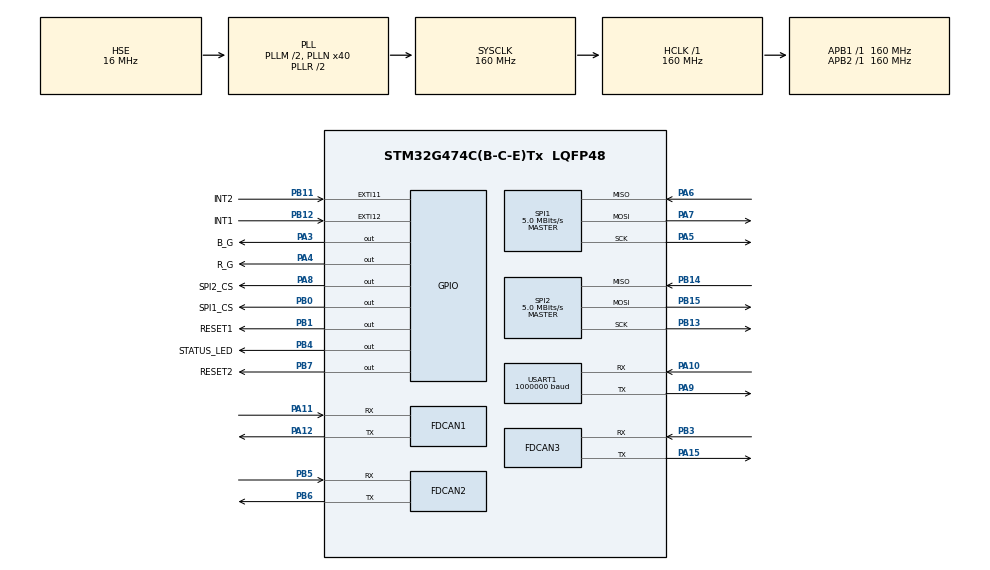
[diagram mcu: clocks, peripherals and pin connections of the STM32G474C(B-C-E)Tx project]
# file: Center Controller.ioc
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Dma.Request0=USART1_RX
Dma.Request1=USART1_TX
Dma.USART1_RX.0.Direction=DMA_PERIPH_TO_MEMORY
Dma.USART1_RX.0.EventEnable=DISABLE
Dma.USART1_RX.0.Instance=DMA1_Channel1
Dma.USART1_RX.0.MemDataAlignment=DMA_MDATAALIGN_BYTE
Dma.USART1_RX.0.MemInc=DMA_MINC_ENABLE
Dma.USART1_RX.0.Mode=DMA_CIRCULAR
Dma.USART1_RX.0.PeriphDataAlignment=DMA_PDATAALIGN_BYTE
Dma.USART1_RX.0.PeriphInc=DMA_PINC_DISABLE
Dma.USART1_RX.0.Polarity=HAL_DMAMUX_REQ_GEN_RISING
Dma.USART1_RX.0.Priority=DMA_PRIORITY_HIGH
Dma.USART1_RX.0.RequestNumber=1
Dma.USART1_RX.0.SignalID=NONE
Dma.USART1_RX.0.SyncEnable=DISABLE
Dma.USART1_RX.0.SyncPolarity=HAL_DMAMUX_SYNC_NO_EVENT
Dma.USART1_RX.0.SyncRequestNumber=1
Dma.USART1_RX.0.SyncSignalID=NONE
Dma.USART1_TX.1.Direction=DMA_MEMORY_TO_PERIPH
Dma.USART1_TX.1.EventEnable=DISABLE
Dma.USART1_TX.1.Instance=DMA1_Channel2
Dma.USART1_TX.1.MemDataAlignment=DMA_MDATAALIGN_BYTE
Dma.USART1_TX.1.MemInc=DMA_MINC_ENABLE
Dma.USART1_TX.1.Mode=DMA_NORMAL
Dma.USART1_TX.1.PeriphDataAlignment=DMA_PDATAALIGN_BYTE
Dma.USART1_TX.1.PeriphInc=DMA_PINC_DISABLE
Dma.USART1_TX.1.Polarity=HAL_DMAMUX_REQ_GEN_RISING
Dma.USART1_TX.1.Priority=DMA_PRIORITY_MEDIUM
Dma.USART1_TX.1.RequestNumber=1
Dma.USART1_TX.1.SignalID=NONE
Dma.USART1_TX.1.SyncEnable=DISABLE
Dma.USART1_TX.1.SyncPolarity=HAL_DMAMUX_SYNC_NO_EVENT
Dma.USART1_TX.1.SyncRequestNumber=1
Dma.USART1_TX.1.SyncSignalID=NONE
FDCAN1.AutoRetransmission=ENABLE
FDCAN1.CalculateBaudRateData=1000000
FDCAN1.CalculateBaudRateNominal=1000000
FDCAN1.CalculateTimeBitData=1000
FDCAN1.CalculateTimeBitNominal=1000
FDCAN1.CalculateTimeQuantumData=50.0
FDCAN1.CalculateTimeQuantumNominal=50.0
FDCAN1.ClockDivider=FDCAN_CLOCK_DIV1
FDCAN1.DataPrescaler=2
FDCAN1.DataSyncJumpWidth=4
FDCAN1.DataTimeSeg1=15
FDCAN1.DataTimeSeg2=4
FDCAN1.ExtFiltersNbr=0
FDCAN1.FrameFormat=FDCAN_FRAME_CLASSIC
FDCAN1.Mode=FDCAN_MODE_NORMAL
FDCAN1.NominalPrescaler=2
FDCAN1.NominalSyncJumpWidth=4
FDCAN1.NominalTimeSeg1=15
FDCAN1.NominalTimeSeg2=4
FDCAN1.ProtocolException=DISABLE
FDCAN1.StdFiltersNbr=4
FDCAN1.TransmitPause=DISABLE
FDCAN1.TxFifoQueueMode=FDCAN_TX_QUEUE_OPERATION
FDCAN2.AutoRetransmission=ENABLE
FDCAN2.CalculateBaudRateData=1000000
FDCAN2.CalculateBaudRateNominal=1000000
FDCAN2.CalculateTimeBitData=1000
FDCAN2.CalculateTimeBitNominal=1000
FDCAN2.CalculateTimeQuantumData=50.0
FDCAN2.CalculateTimeQuantumNominal=50.0
FDCAN2.ClockDivider=FDCAN_CLOCK_DIV1
FDCAN2.DataPrescaler=2
FDCAN2.DataSyncJumpWidth=4
FDCAN2.DataTimeSeg1=15
FDCAN2.DataTimeSeg2=4
FDCAN2.ExtFiltersNbr=0
FDCAN2.FrameFormat=FDCAN_FRAME_CLASSIC
FDCAN2.Mode=FDCAN_MODE_NORMAL
FDCAN2.NominalPrescaler=2
FDCAN2.NominalSyncJumpWidth=4
FDCAN2.NominalTimeSeg1=15
FDCAN2.NominalTimeSeg2=4
FDCAN2.ProtocolException=DISABLE
FDCAN2.StdFiltersNbr=2
FDCAN2.TransmitPause=DISABLE
FDCAN2.TxFifoQueueMode=FDCAN_TX_QUEUE_OPERATION
FDCAN3.AutoRetransmission=ENABLE
FDCAN3.CalculateBaudRateData=1000000
FDCAN3.CalculateBaudRateNominal=1000000
FDCAN3.CalculateTimeBitData=1000
FDCAN3.CalculateTimeBitNominal=1000
FDCAN3.CalculateTimeQuantumData=50.0
FDCAN3.CalculateTimeQuantumNominal=50.0
FDCAN3.ClockDivider=FDCAN_CLOCK_DIV1
FDCAN3.DataPrescaler=2
FDCAN3.DataSyncJumpWidth=4
FDCAN3.DataTimeSeg1=15
FDCAN3.DataTimeSeg2=4
FDCAN3.ExtFiltersNbr=0
FDCAN3.FrameFormat=FDCAN_FRAME_CLASSIC
FDCAN3.Mode=FDCAN_MODE_NORMAL
FDCAN3.NominalPrescaler=2
FDCAN3.NominalSyncJumpWidth=4
FDCAN3.NominalTimeSeg1=15
FDCAN3.NominalTimeSeg2=4
FDCAN3.ProtocolException=DISABLE
FDCAN3.StdFiltersNbr=2
FDCAN3.TransmitPause=DISABLE
FDCAN3.TxFifoQueueMode=FDCAN_TX_QUEUE_OPERATION
Mcu.Family=STM32G4
Mcu.Name=STM32G474C(B-C-E)Tx
Mcu.Package=LQFP48
NVIC.DMA1_Channel1_IRQn=true\:5\:0\:true\:false\:true\:false\:true\:true
NVIC.DMA1_Channel2_IRQn=true\:5\:0\:true\:false\:true\:false\:true\:true
NVIC.EXTI15_10_IRQn=true\:3\:0\:true\:false\:true\:false\:true\:true
NVIC.FDCAN1_IT0_IRQn=true\:1\:0\:true\:false\:true\:false\:true\:true
NVIC.FDCAN2_IT0_IRQn=true\:3\:0\:true\:false\:true\:false\:true\:true
NVIC.FDCAN3_IT0_IRQn=true\:3\:0\:true\:false\:true\:false\:true\:true
NVIC.PriorityGroup=NVIC_PRIORITYGROUP_4
NVIC.TIM7_DAC_IRQn=true\:2\:0\:true\:false\:true\:false\:true\:true
NVIC.USART1_IRQn=true\:5\:0\:true\:false\:true\:false\:true\:true
PA10.Mode=Asynchronous
PA10.Signal=USART1_RX
PA11.Mode=FDCAN_Activate
PA11.Signal=FDCAN1_RX
PA12.Mode=FDCAN_Activate
PA12.Signal=FDCAN1_TX
PA13.Mode=Serial_Wire
PA13.Signal=SYS_JTMS-SWDIO
PA14.Mode=Serial_Wire
PA14.Signal=SYS_JTCK-SWCLK
PA15.Mode=FDCAN_Activate
PA15.Signal=FDCAN3_TX
PA3.GPIO_Label=B_G
PA3.GPIO_ModeDefaultOutputPP=GPIO_MODE_OUTPUT_PP
PA3.GPIO_PuPd=GPIO_NOPULL
PA3.GPIO_Speed=GPIO_SPEED_FREQ_LOW
PA3.PinState=GPIO_PIN_RESET
PA3.Signal=GPIO_Output
PA4.GPIO_Label=R_G
PA4.GPIO_ModeDefaultOutputPP=GPIO_MODE_OUTPUT_PP
PA4.GPIO_PuPd=GPIO_NOPULL
PA4.GPIO_Speed=GPIO_SPEED_FREQ_LOW
PA4.PinState=GPIO_PIN_RESET
PA4.Signal=GPIO_Output
PA5.Mode=Full_Duplex_Master
PA5.Signal=SPI1_SCK
PA6.Mode=Full_Duplex_Master
PA6.Signal=SPI1_MISO
PA7.Mode=Full_Duplex_Master
PA7.Signal=SPI1_MOSI
PA8.GPIO_Label=SPI2_CS
PA8.GPIO_ModeDefaultOutputPP=GPIO_MODE_OUTPUT_PP
PA8.GPIO_PuPd=GPIO_NOPULL
PA8.GPIO_Speed=GPIO_SPEED_FREQ_LOW
PA8.PinState=GPIO_PIN_SET
PA8.Signal=GPIO_Output
PA9.Mode=Asynchronous
PA9.Signal=USART1_TX
PB0.GPIO_Label=SPI1_CS
PB0.GPIO_ModeDefaultOutputPP=GPIO_MODE_OUTPUT_PP
PB0.GPIO_PuPd=GPIO_NOPULL
PB0.GPIO_Speed=GPIO_SPEED_FREQ_LOW
PB0.PinState=GPIO_PIN_SET
PB0.Signal=GPIO_Output
PB1.GPIO_Label=RESET1
PB1.GPIO_ModeDefaultOutputPP=GPIO_MODE_OUTPUT_PP
PB1.GPIO_PuPd=GPIO_NOPULL
PB1.GPIO_Speed=GPIO_SPEED_FREQ_LOW
PB1.PinState=GPIO_PIN_SET
PB1.Signal=GPIO_Output
PB11.GPIO_Label=INT2
PB11.GPIO_ModeDefaultEXTI=GPIO_MODE_IT_FALLING
PB11.GPIO_PuPd=GPIO_NOPULL
PB11.Signal=GPXTI11
PB12.GPIO_Label=INT1
PB12.GPIO_ModeDefaultEXTI=GPIO_MODE_IT_FALLING
PB12.GPIO_PuPd=GPIO_NOPULL
PB12.Signal=GPXTI12
PB13.Mode=Full_Duplex_Master
PB13.Signal=SPI2_SCK
PB14.Mode=Full_Duplex_Master
PB14.Signal=SPI2_MISO
PB15.Mode=Full_Duplex_Master
PB15.Signal=SPI2_MOSI
PB3.Mode=FDCAN_Activate
PB3.Signal=FDCAN3_RX
PB4.GPIO_Label=STATUS_LED
PB4.GPIO_ModeDefaultOutputPP=GPIO_MODE_OUTPUT_PP
PB4.GPIO_PuPd=GPIO_NOPULL
PB4.GPIO_Speed=GPIO_SPEED_FREQ_LOW
PB4.PinState=GPIO_PIN_RESET
PB4.Signal=GPIO_Output
PB5.Mode=FDCAN_Activate
PB5.Signal=FDCAN2_RX
PB6.Mode=FDCAN_Activate
PB6.Signal=FDCAN2_TX
PB7.GPIO_Label=RESET2
PB7.GPIO_ModeDefaultOutputPP=GPIO_MODE_OUTPUT_PP
PB7.GPIO_PuPd=GPIO_NOPULL
PB7.GPIO_Speed=GPIO_SPEED_FREQ_LOW
PB7.PinState=GPIO_PIN_SET
PB7.Signal=GPIO_Output
PF0-OSC_IN.Mode=HSE-External-Oscillator
PF0-OSC_IN.Signal=RCC_OSC_IN
PF1-OSC_OUT.Mode=HSE-External-Oscillator
PF1-OSC_OUT.Signal=RCC_OSC_OUT
ProjectManager.HeapSize=0x200
ProjectManager.StackSize=0x1000
ProjectManager.TargetToolchain=CMake
RCC.ADC12Freq_Value=160000000
RCC.ADC345Freq_Value=160000000
RCC.AHBFreq_Value=160000000
RCC.APB1Freq_Value=160000000
RCC.APB1TimFreq_Value=160000000
RCC.APB2Freq_Value=160000000
RCC.APB2TimFreq_Value=160000000
RCC.CK48CLockSelection=RCC_USBCLKSOURCE_PLL
RCC.CortexFreq_Value=160000000
RCC.EXTERNAL_CLOCK_VALUE=12288000
RCC.FDCANCLockSelection=RCC_FDCANCLKSOURCE_PLL
RCC.HCLKFreq_Value=160000000
RCC.HSE_VALUE=16000000
RCC.HSI48_VALUE=48000000
RCC.HSI_VALUE=16000000
RCC.LSE_VALUE=32768
RCC.PLLM=RCC_PLLM_DIV2
RCC.PLLN=40
RCC.PLLP=RCC_PLLP_DIV2
RCC.PLLQ=RCC_PLLQ_DIV8
RCC.PLLR=RCC_PLLR_DIV2
RCC.PLLSourceVirtual=RCC_PLLSOURCE_HSE
RCC.PWR_Regulator_Voltage_Scale=PWR_REGULATOR_VOLTAGE_SCALE1_BOOST
RCC.SYSCLKFreq_VALUE=160000000
RCC.SYSCLKSource=RCC_SYSCLKSOURCE_PLLCLK
RCC.USART1CLockSelection=RCC_USART1CLKSOURCE_PCLK2
RCC.USART2CLockSelection=RCC_USART2CLKSOURCE_PCLK1
RCC.USBFreq_Value=40000000
RCC.VCOOutputFreq_Value=320000000
SPI1.BaudRatePrescaler=SPI_BAUDRATEPRESCALER_32
SPI1.CLKPhase=SPI_PHASE_1EDGE
SPI1.CLKPolarity=SPI_POLARITY_LOW
SPI1.CRCCalculation=SPI_CRCCALCULATION_DISABLE
SPI1.CalculateBaudRate=5.0 MBits/s
SPI1.DataSize=SPI_DATASIZE_8BIT
SPI1.Direction=SPI_DIRECTION_2LINES
SPI1.FirstBit=SPI_FIRSTBIT_MSB
SPI1.Mode=SPI_MODE_MASTER
SPI1.NSS=SPI_NSS_SOFT
SPI1.NSSPMode=SPI_NSS_PULSE_DISABLE
SPI1.TIMode=SPI_TIMODE_DISABLE
SPI1.VirtualType=VM_MASTER
SPI2.BaudRatePrescaler=SPI_BAUDRATEPRESCALER_32
SPI2.CLKPhase=SPI_PHASE_1EDGE
SPI2.CLKPolarity=SPI_POLARITY_LOW
SPI2.CRCCalculation=SPI_CRCCALCULATION_DISABLE
SPI2.CalculateBaudRate=5.0 MBits/s
SPI2.DataSize=SPI_DATASIZE_8BIT
SPI2.Direction=SPI_DIRECTION_2LINES
SPI2.FirstBit=SPI_FIRSTBIT_MSB
SPI2.Mode=SPI_MODE_MASTER
SPI2.NSS=SPI_NSS_SOFT
SPI2.NSSPMode=SPI_NSS_PULSE_DISABLE
SPI2.TIMode=SPI_TIMODE_DISABLE
SPI2.VirtualType=VM_MASTER
TIM7.AutoReloadPreload=TIM_AUTORELOAD_PRELOAD_DISABLE
TIM7.PeriodNoDither=999
TIM7.Prescaler=159
TIM7.TIM_MasterOutputTrigger=TIM_TRGO_RESET
USART1.BaudRate=1000000
USART1.ClockPrescaler=PRESCALER_DIV1
USART1.FIFOMode=FIFOMODE_DISABLE
USART1.Mode=MODE_TX_RX
USART1.OverSampling=UART_OVERSAMPLING_16
USART1.Parity=PARITY_NONE
USART1.StopBits=STOPBITS_1
USART1.VirtualMode-Asynchronous=VM_ASYNC
USART1.WordLength=WORDLENGTH_8B
VP_SYS_VS_DBSignals.Mode=DisableDeadBatterySignals
VP_TIM7_VS_ClockSourceINT.Mode=Enable_Timer
board=custom

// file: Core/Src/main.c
/* USER CODE BEGIN Header */
/**
  ******************************************************************************
  * @file           : main.c
  * @brief          : Main program body
  ******************************************************************************
  * @attention
  *
  * Copyright (c) 2026 STMicroelectronics.
  * All rights reserved.
  *
  * This software is licensed under terms that can be found in the LICENSE file
  * in the root directory of this software component.
  * If no LICENSE file comes with this software, it is provided AS-IS.
  *
  ******************************************************************************
  */
/* USER CODE END Header */
#include "main.h"
#include "dma.h"
#include "fdcan.h"
#include "spi.h"
#include "tim.h"
#include "usart.h"
#include "gpio.h"

/* USER CODE BEGIN Includes */
#include "board_app.h"
#include "status_led.h"

/* USER CODE END Includes */

void SystemClock_Config(void);

int main(void)
{

  /* MCU Configuration--------------------------------------------------------*/

  /* Reset of all peripherals, Initializes the Flash interface and the Systick. */
  HAL_Init();

  /* Configure the system clock */
  SystemClock_Config();

  /* Initialize all configured peripherals */
  MX_GPIO_Init();
  MX_DMA_Init();
  MX_FDCAN1_Init();
  MX_FDCAN2_Init();
  MX_FDCAN3_Init();
  MX_SPI1_Init();
  MX_SPI2_Init();
  MX_USART1_UART_Init();
  MX_TIM7_Init();
  /* USER CODE BEGIN 2 */
  BoardApp_Init();
  StatusLed_Init(HAL_GetTick());

  /* USER CODE END 2 */

  /* Infinite loop */
  while (1)
  {

    /* USER CODE BEGIN 3 */
    BoardApp_Process();
    StatusLed_Process(HAL_GetTick());
  }
  /* USER CODE END 3 */
}

void SystemClock_Config(void)
{
  RCC_OscInitTypeDef RCC_OscInitStruct = {0};
  RCC_ClkInitTypeDef RCC_ClkInitStruct = {0};

  /** Configure the main internal regulator output voltage
  */
  HAL_PWREx_ControlVoltageScaling(PWR_REGULATOR_VOLTAGE_SCALE1_BOOST);

  /** Initializes the RCC Oscillators according to the specified parameters
  * in the RCC_OscInitTypeDef structure.
  */
  RCC_OscInitStruct.OscillatorType = RCC_OSCILLATORTYPE_HSE;
  RCC_OscInitStruct.HSEState = RCC_HSE_ON;
  RCC_OscInitStruct.PLL.PLLState = RCC_PLL_ON;
  RCC_OscInitStruct.PLL.PLLSource = RCC_PLLSOURCE_HSE;
  RCC_OscInitStruct.PLL.PLLM = RCC_PLLM_DIV2;
  RCC_OscInitStruct.PLL.PLLN = 40;
  RCC_OscInitStruct.PLL.PLLP = RCC_PLLP_DIV2;
  RCC_OscInitStruct.PLL.PLLQ = RCC_PLLQ_DIV8;
  RCC_OscInitStruct.PLL.PLLR = RCC_PLLR_DIV2;
  if (HAL_RCC_OscConfig(&RCC_OscInitStruct) != HAL_OK)
  {
    Error_Handler();
  }

  /** Initializes the CPU, AHB and APB buses clocks
  */
  RCC_ClkInitStruct.ClockType = RCC_CLOCKTYPE_HCLK|RCC_CLOCKTYPE_SYSCLK
                              |RCC_CLOCKTYPE_PCLK1|RCC_CLOCKTYPE_PCLK2;
  RCC_ClkInitStruct.SYSCLKSource = RCC_SYSCLKSOURCE_PLLCLK;
  RCC_ClkInitStruct.AHBCLKDivider = RCC_SYSCLK_DIV1;
  RCC_ClkInitStruct.APB1CLKDivider = RCC_HCLK_DIV1;
  RCC_ClkInitStruct.APB2CLKDivider = RCC_HCLK_DIV1;

  if (HAL_RCC_ClockConfig(&RCC_ClkInitStruct, FLASH_LATENCY_4) != HAL_OK)
  {
    Error_Handler();
  }
}

void Error_Handler(void)
{
  __disable_irq();
  while (1)
  {
  }
}
